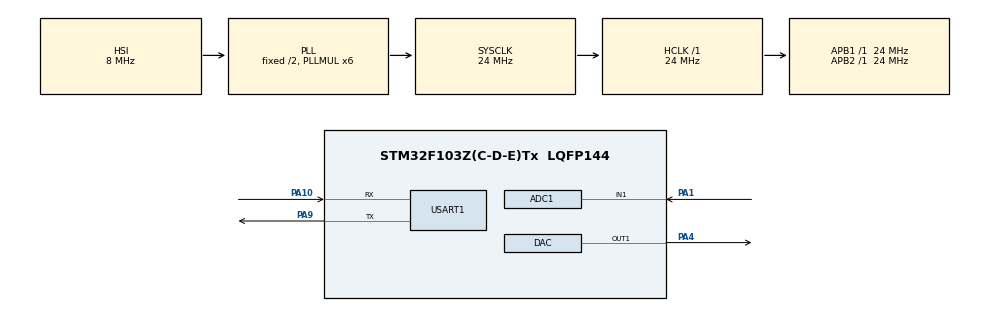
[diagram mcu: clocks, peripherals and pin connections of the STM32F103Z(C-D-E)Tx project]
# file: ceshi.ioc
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ADC1.Channel-0\#ChannelRegularConversion=ADC_CHANNEL_1
ADC1.ContinuousConvMode=DISABLE
ADC1.DataAlign=ADC_DATAALIGN_RIGHT
ADC1.DiscontinuousConvMode=DISABLE
ADC1.EnableAnalogWatchDog=false
ADC1.EnableRegularConversion=ENABLE
ADC1.ExternalTrigConv=ADC_SOFTWARE_START
ADC1.InjNumberOfConversion=0
ADC1.NbrOfConversion=1
ADC1.NbrOfConversionFlag=1
ADC1.Rank-0\#ChannelRegularConversion=1
ADC1.SamplingTime-0\#ChannelRegularConversion=ADC_SAMPLETIME_1CYCLE_5
ADC1.ScanConvMode=ADC_SCAN_DISABLE
ADC1.master=1
Mcu.Family=STM32F1
Mcu.Name=STM32F103Z(C-D-E)Tx
Mcu.Package=LQFP144
NVIC.PriorityGroup=NVIC_PRIORITYGROUP_4
PA1.Signal=ADCx_IN1
PA10.Mode=Asynchronous
PA10.Signal=USART1_RX
PA13.Mode=Serial_Wire
PA13.Signal=SYS_JTMS-SWDIO
PA14.Mode=Serial_Wire
PA14.Signal=SYS_JTCK-SWCLK
PA4.Signal=COMP_DAC1_group
PA9.Mode=Asynchronous
PA9.Signal=USART1_TX
ProjectManager.HeapSize=0x200
ProjectManager.StackSize=0x400
ProjectManager.TargetToolchain=MDK-ARM V5
RCC.AHBFreq_Value=24000000
RCC.APB1Freq_Value=24000000
RCC.APB1TimFreq_Value=24000000
RCC.APB2Freq_Value=24000000
RCC.APB2TimFreq_Value=24000000
RCC.HCLKFreq_Value=24000000
RCC.PLLMUL=RCC_PLL_MUL6
RCC.SYSCLKFreq_VALUE=24000000
RCC.SYSCLKSource=RCC_SYSCLKSOURCE_PLLCLK
RCC.USBFreq_Value=24000000
SH.ADCx_IN1.0=ADC1_IN1,IN1
SH.COMP_DAC1_group.0=DAC_OUT1,DAC_OUT1
USART1.VirtualMode=VM_ASYNC
board=custom

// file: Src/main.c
/**
  ******************************************************************************
  * @file           : main.c
  * @brief          : Main program body
  ******************************************************************************
  ** This notice applies to any and all portions of this file
  * that are not between comment pairs USER CODE BEGIN and
  * USER CODE END. Other portions of this file, whether
  * inserted by the user or by software development tools
  * are owned by their respective copyright owners.
  *
  * COPYRIGHT(c) 2019 STMicroelectronics
  *
  * Redistribution and use in source and binary forms, with or without modification,
  * are permitted provided that the following conditions are met:
  *   1. Redistributions of source code must retain the above copyright notice,
  *      this list of conditions and the following disclaimer.
  *   2. Redistributions in binary form must reproduce the above copyright notice,
  *      this list of conditions and the following disclaimer in the documentation
  *      and/or other materials provided with the distribution.
  *   3. Neither the name of STMicroelectronics nor the names of its contributors
  *      may be used to endorse or promote products derived from this software
  *      without specific prior written permission.
  *
  * THIS SOFTWARE IS PROVIDED BY THE COPYRIGHT HOLDERS AND CONTRIBUTORS "AS IS"
  * AND ANY EXPRESS OR IMPLIED WARRANTIES, INCLUDING, BUT NOT LIMITED TO, THE
  * IMPLIED WARRANTIES OF MERCHANTABILITY AND FITNESS FOR A PARTICULAR PURPOSE ARE
  * DISCLAIMED. IN NO EVENT SHALL THE COPYRIGHT HOLDER OR CONTRIBUTORS BE LIABLE
  * FOR ANY DIRECT, INDIRECT, INCIDENTAL, SPECIAL, EXEMPLARY, OR CONSEQUENTIAL
  * DAMAGES (INCLUDING, BUT NOT LIMITED TO, PROCUREMENT OF SUBSTITUTE GOODS OR
  * SERVICES; LOSS OF USE, DATA, OR PROFITS; OR BUSINESS INTERRUPTION) HOWEVER
  * CAUSED AND ON ANY THEORY OF LIABILITY, WHETHER IN CONTRACT, STRICT LIABILITY,
  * OR TORT (INCLUDING NEGLIGENCE OR OTHERWISE) ARISING IN ANY WAY OUT OF THE USE
  * OF THIS SOFTWARE, EVEN IF ADVISED OF THE POSSIBILITY OF SUCH DAMAGE.
  *
  ******************************************************************************
  */
#include "main.h"
#include "stm32f1xx_hal.h"

ADC_HandleTypeDef hadc1;
int	ADC_convertedvalue;
DAC_HandleTypeDef hdac;
int8_t low;
int8_t high;
UART_HandleTypeDef huart1;

/* USER CODE BEGIN PV */
/* Private variables ---------------------------------------------------------*/

/* USER CODE END PV */

void SystemClock_Config(void);
static void MX_GPIO_Init(void);
static void MX_ADC1_Init(void);
static void MX_DAC_Init(void);
static void MX_USART1_UART_Init(void);

/* USER CODE BEGIN PFP */
/* Private function prototypes -----------------------------------------------*/

/* USER CODE END PFP */

int main(void)
{

  /* MCU Configuration----------------------------------------------------------*/

  /* Reset of all peripherals, Initializes the Flash interface and the Systick. */
  HAL_Init();

  /* Configure the system clock */
  SystemClock_Config();

  /* Initialize all configured peripherals */
  MX_GPIO_Init();
  MX_ADC1_Init();
  MX_DAC_Init();
  MX_USART1_UART_Init();

  /* Infinite loop */
  /* USER CODE BEGIN WHILE */
  while (1)
  {
		HAL_ADC_Start(&hadc1);
		HAL_ADC_PollForConversion(&hadc1,10);
		ADC_convertedvalue=HAL_ADC_GetValue(&hadc1);
		HAL_DAC_SetValue(&hdac,DAC1_CHANNEL_1,DAC_ALIGN_12B_R,ADC_convertedvalue);
		HAL_DAC_Start(&hdac,DAC_CHANNEL_1);
		low = ADC_convertedvalue & (0xff) ;
		high = (ADC_convertedvalue>>8) & (0xff) ;
		HAL_UART_Transmit(&huart1, &high , sizeof(high), 5000);
		while(__HAL_UART_GET_FLAG(&huart1,UART_FLAG_TC)!=SET);
		HAL_UART_Transmit(&huart1, &low , sizeof(low), 5000);
		while(__HAL_UART_GET_FLAG(&huart1,UART_FLAG_TC)!=SET);
		HAL_Delay(1);
  /* USER CODE END WHILE */

  }

}

void SystemClock_Config(void)
{

  RCC_OscInitTypeDef RCC_OscInitStruct;
  RCC_ClkInitTypeDef RCC_ClkInitStruct;
  RCC_PeriphCLKInitTypeDef PeriphClkInit;

    /**Initializes the CPU, AHB and APB busses clocks
    */
  RCC_OscInitStruct.OscillatorType = RCC_OSCILLATORTYPE_HSI;
  RCC_OscInitStruct.HSIState = RCC_HSI_ON;
  RCC_OscInitStruct.HSICalibrationValue = 16;
  RCC_OscInitStruct.PLL.PLLState = RCC_PLL_ON;
  RCC_OscInitStruct.PLL.PLLSource = RCC_PLLSOURCE_HSI_DIV2;
  RCC_OscInitStruct.PLL.PLLMUL = RCC_PLL_MUL6;
  if (HAL_RCC_OscConfig(&RCC_OscInitStruct) != HAL_OK)
  {
    _Error_Handler(__FILE__, __LINE__);
  }

    /**Initializes the CPU, AHB and APB busses clocks
    */
  RCC_ClkInitStruct.ClockType = RCC_CLOCKTYPE_HCLK|RCC_CLOCKTYPE_SYSCLK
                              |RCC_CLOCKTYPE_PCLK1|RCC_CLOCKTYPE_PCLK2;
  RCC_ClkInitStruct.SYSCLKSource = RCC_SYSCLKSOURCE_PLLCLK;
  RCC_ClkInitStruct.AHBCLKDivider = RCC_SYSCLK_DIV1;
  RCC_ClkInitStruct.APB1CLKDivider = RCC_HCLK_DIV1;
  RCC_ClkInitStruct.APB2CLKDivider = RCC_HCLK_DIV1;

  if (HAL_RCC_ClockConfig(&RCC_ClkInitStruct, FLASH_LATENCY_0) != HAL_OK)
  {
    _Error_Handler(__FILE__, __LINE__);
  }

  PeriphClkInit.PeriphClockSelection = RCC_PERIPHCLK_ADC;
  PeriphClkInit.AdcClockSelection = RCC_ADCPCLK2_DIV2;
  if (HAL_RCCEx_PeriphCLKConfig(&PeriphClkInit) != HAL_OK)
  {
    _Error_Handler(__FILE__, __LINE__);
  }

    /**Configure the Systick interrupt time
    */
  HAL_SYSTICK_Config(HAL_RCC_GetHCLKFreq()/1000);

    /**Configure the Systick
    */
  HAL_SYSTICK_CLKSourceConfig(SYSTICK_CLKSOURCE_HCLK);

  /* SysTick_IRQn interrupt configuration */
  HAL_NVIC_SetPriority(SysTick_IRQn, 0, 0);
}

/* ADC1 init function */
static void MX_ADC1_Init(void)
{

  ADC_ChannelConfTypeDef sConfig;

    /**Common config
    */
  hadc1.Instance = ADC1;
  hadc1.Init.ScanConvMode = ADC_SCAN_DISABLE;
  hadc1.Init.ContinuousConvMode = DISABLE;
  hadc1.Init.DiscontinuousConvMode = DISABLE;
  hadc1.Init.ExternalTrigConv = ADC_SOFTWARE_START;
  hadc1.Init.DataAlign = ADC_DATAALIGN_RIGHT;
  hadc1.Init.NbrOfConversion = 1;
  if (HAL_ADC_Init(&hadc1) != HAL_OK)
  {
    _Error_Handler(__FILE__, __LINE__);
  }

    /**Configure Regular Channel
    */
  sConfig.Channel = ADC_CHANNEL_1;
  sConfig.Rank = ADC_REGULAR_RANK_1;
  sConfig.SamplingTime = ADC_SAMPLETIME_1CYCLE_5;
  if (HAL_ADC_ConfigChannel(&hadc1, &sConfig) != HAL_OK)
  {
    _Error_Handler(__FILE__, __LINE__);
  }

}

/* DAC init function */
static void MX_DAC_Init(void)
{

  DAC_ChannelConfTypeDef sConfig;

    /**DAC Initialization
    */
  hdac.Instance = DAC;
  if (HAL_DAC_Init(&hdac) != HAL_OK)
  {
    _Error_Handler(__FILE__, __LINE__);
  }

    /**DAC channel OUT1 config
    */
  sConfig.DAC_Trigger = DAC_TRIGGER_NONE;
  sConfig.DAC_OutputBuffer = DAC_OUTPUTBUFFER_ENABLE;
  if (HAL_DAC_ConfigChannel(&hdac, &sConfig, DAC_CHANNEL_1) != HAL_OK)
  {
    _Error_Handler(__FILE__, __LINE__);
  }

}

/* USART1 init function */
static void MX_USART1_UART_Init(void)
{

  huart1.Instance = USART1;
  huart1.Init.BaudRate = 115200;
  huart1.Init.WordLength = UART_WORDLENGTH_8B;
  huart1.Init.StopBits = UART_STOPBITS_1;
  huart1.Init.Parity = UART_PARITY_NONE;
  huart1.Init.Mode = UART_MODE_TX_RX;
  huart1.Init.HwFlowCtl = UART_HWCONTROL_NONE;
  huart1.Init.OverSampling = UART_OVERSAMPLING_16;
  if (HAL_UART_Init(&huart1) != HAL_OK)
  {
    _Error_Handler(__FILE__, __LINE__);
  }

}

/** Configure pins as
        * Analog
        * Input
        * Output
        * EVENT_OUT
        * EXTI
*/
static void MX_GPIO_Init(void)
{

  /* GPIO Ports Clock Enable */
  __HAL_RCC_GPIOA_CLK_ENABLE();

}

void _Error_Handler(char *file, int line)
{
  while(1)
  {
  }
}

/************************ (C) COPYRIGHT STMicroelectronics *****END OF FILE****/
